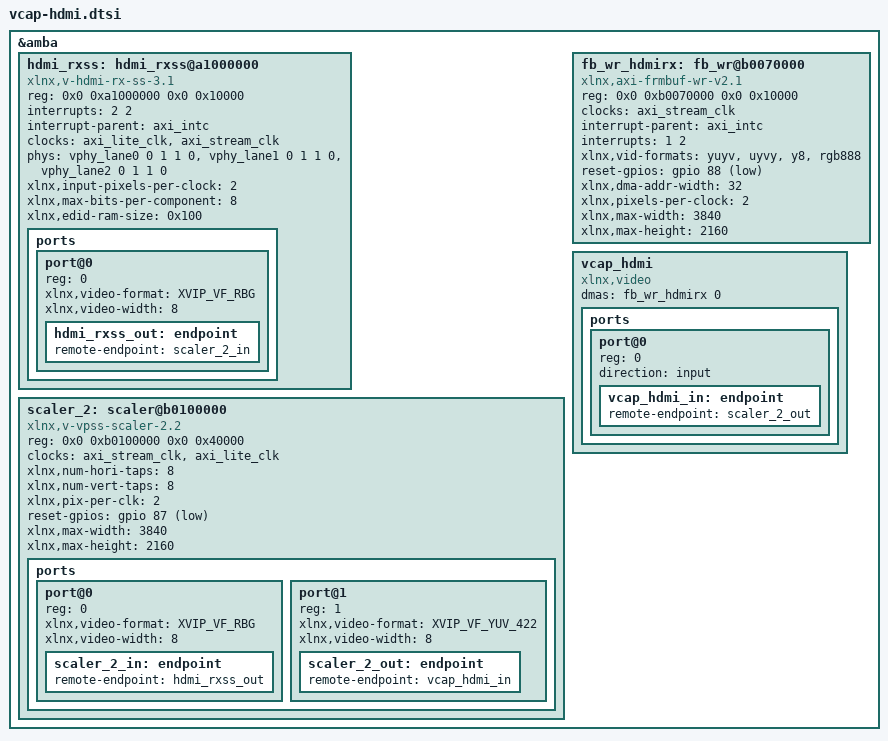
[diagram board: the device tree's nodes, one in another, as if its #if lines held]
#include <dt-bindings/media/xilinx-vip.h>

&amba {
	hdmi_rxss: hdmi_rxss@a1000000 {
		compatible = "xlnx,v-hdmi-rx-ss-3.1";
		reg = <0x0 0xa1000000 0x0 0x10000>;
		reg-names = "hdmi-rxss";
		interrupts = <2 2>;
		interrupt-parent = <&axi_intc>;
		interrupt-names = "hdmirx";
		clocks = <&axi_lite_clk>, <&axi_stream_clk>;
		clock-names = "s_axi_cpu_aclk", "s_axis_video_aclk";
		phys = <&vphy_lane0 0 1 1 0>, <&vphy_lane1 0 1 1 0>, <&vphy_lane2 0 1 1 0>;
		phy-names = "hdmi-phy0", "hdmi-phy1", "hdmi-phy2";
		xlnx,input-pixels-per-clock = <2>;
		xlnx,max-bits-per-component = <8>;
		xlnx,edid-ram-size = <0x100>;

		ports {
			#address-cells = <1>;
			#size-cells = <0>;

			port@0 {
				reg = <0>;

				xlnx,video-format = <XVIP_VF_RBG>;
				xlnx,video-width = <8>;

				hdmi_rxss_out: endpoint {
					remote-endpoint = <&scaler_2_in>;
				};
			};
		};
	};

	scaler_2: scaler@b0100000 {
		compatible = "xlnx,v-vpss-scaler-2.2";
		reg = <0x0 0xb0100000 0x0 0x40000>;
		clock-names = "aclk_axis", "aclk_ctrl";
		clocks = <&axi_stream_clk>, <&axi_lite_clk>;
		xlnx,num-hori-taps = <8>;
		xlnx,num-vert-taps = <8>;
		xlnx,pix-per-clk = <2>;
		reset-gpios = <&gpio 87 1>;
		xlnx,max-width = <3840>;
		xlnx,max-height = <2160>;

		ports {
			#address-cells = <1>;
			#size-cells = <0>;

			port@0 {
				reg = <0>;

				xlnx,video-format = <XVIP_VF_RBG>;
				xlnx,video-width = <8>;

				scaler_2_in: endpoint {
					remote-endpoint = <&hdmi_rxss_out>;
				};
			};
			port@1 {
				reg = <1>;

				xlnx,video-format = <XVIP_VF_YUV_422>;
				xlnx,video-width = <8>;

				scaler_2_out: endpoint {
					remote-endpoint = <&vcap_hdmi_in>;
				};
			};
		};
	};

	fb_wr_hdmirx: fb_wr@b0070000 {
		compatible = "xlnx,axi-frmbuf-wr-v2.1";
		reg = <0x0 0xb0070000 0x0 0x10000>;
		#dma-cells = <1>;
		clock-names = "ap_clk";
		clocks = <&axi_stream_clk>;
		interrupt-parent = <&axi_intc>;
		interrupts = <1 2>;
#ifdef DESIGN_BASE_TRD
		xlnx,vid-formats = "yuyv", "uyvy", "y8";
#endif
#ifdef DESIGN_RV_SS
		xlnx,vid-formats = "yuyv", "uyvy", "y8", "rgb888";
#endif
		reset-gpios = <&gpio 88 1>;
		xlnx,dma-addr-width = <32>;
		xlnx,pixels-per-clock = <2>;
		xlnx,max-width = <3840>;
		xlnx,max-height = <2160>;
	};

	vcap_hdmi {
		compatible = "xlnx,video";
		dmas = <&fb_wr_hdmirx 0>;
		dma-names = "port0";

		ports {
			#address-cells = <1>;
			#size-cells = <0>;

			port@0 {
				reg = <0>;
				direction = "input";
				vcap_hdmi_in: endpoint {
					remote-endpoint = <&scaler_2_out>;
				};
			};
		};
	};
};
